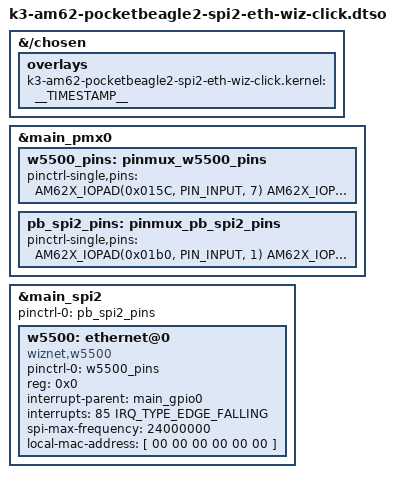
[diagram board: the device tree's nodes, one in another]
// SPDX-License-Identifier: GPL-2.0-only OR MIT
/*
 * DT Overlay for eth-wiz-click connections within the expansion header.
 *
 * https://www.mikroe.com/eth-wiz-click
 * https://download.mikroe.com/documents/add-on-boards/click/eth-wiz/eth-wiz-click-manual-v100.pdf
 *
 * Copyright (C) 2025 Texas Instruments Incorporated - https://www.ti.com/
 *
 */

/dts-v1/;
/plugin/;

#include <dt-bindings/gpio/gpio.h>
#include <dt-bindings/interrupt-controller/irq.h>
#include "ti/k3-pinctrl.h"

/*
 * Helper to show loaded overlays under: /proc/device-tree/chosen/overlays/
*/
&{/chosen} {
	overlays {
		k3-am62-pocketbeagle2-spi2-eth-wiz-click.kernel = __TIMESTAMP__;
	};
};

&main_pmx0 {
	w5500_pins: pinmux_w5500_pins {
		pinctrl-single,pins = <
			AM62X_IOPAD(0x015C, PIN_INPUT, 7) /* P2.03: (AB22) MDIO0_MDIO.GPIO0_85 INT */
			AM62X_IOPAD(0x016C, PIN_INPUT, 7) /* P1.04: (Y18) RGMII2_TD0.GPIO0_89 RESET */
		>;
	};

	pb_spi2_pins: pinmux_pb_spi2_pins {
		pinctrl-single,pins = <
			AM62X_IOPAD(0x01b0, PIN_INPUT, 1) /* (A20) MCASP0_ACLKR.SPI2_CLK */
			AM62X_IOPAD(0x01ac, PIN_INPUT, 1) /* (E19) MCASP0_AFSR.SPI2_CS0 */
			AM62X_IOPAD(0x0194, PIN_INPUT, 1) /* (B19) MCASP0_AXR3.SPI2_D0 */
			AM62X_IOPAD(0x0198, PIN_INPUT, 1) /* (A19) MCASP0_AXR2.SPI2_D1 */
		>;
	};
};

&main_spi2 {
	status = "okay";
	pinctrl-names = "default";
	pinctrl-0 = <&pb_spi2_pins>;

	#address-cells = <1>;
	#size-cells = <0>;

	w5500: ethernet@0 {
		compatible = "wiznet,w5500";
		pinctrl-names = "default";
		pinctrl-0 = <&w5500_pins>;
		reg = <0x0>;
		interrupt-parent = <&main_gpio0>;
		interrupts = <85 IRQ_TYPE_EDGE_FALLING>;
		spi-max-frequency = <24000000>;
		local-mac-address = [ 00 00 00 00 00 00 ];
	};
};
